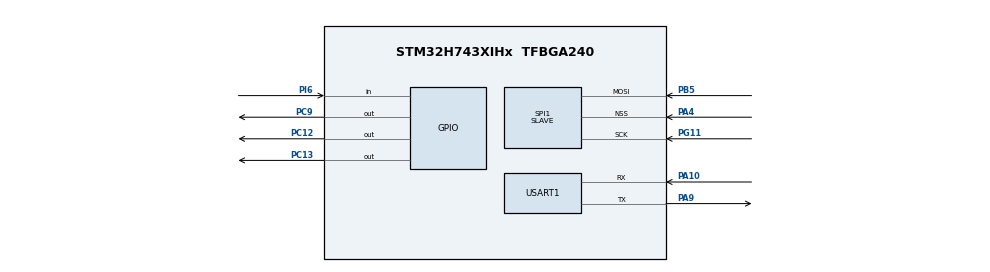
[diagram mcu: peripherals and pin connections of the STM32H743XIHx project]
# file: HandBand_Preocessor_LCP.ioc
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CORTEX_M7.CPU_DCache=Enabled
CORTEX_M7.CPU_ICache=Enabled
CORTEX_M7.default_mode_Activation=1
Dma.Request0=USART1_TX
Dma.Request1=SPI1_RX
Dma.SPI1_RX.1.Direction=DMA_PERIPH_TO_MEMORY
Dma.SPI1_RX.1.EventEnable=DISABLE
Dma.SPI1_RX.1.FIFOMode=DMA_FIFOMODE_DISABLE
Dma.SPI1_RX.1.Instance=DMA1_Stream1
Dma.SPI1_RX.1.MemDataAlignment=DMA_MDATAALIGN_BYTE
Dma.SPI1_RX.1.MemInc=DMA_MINC_ENABLE
Dma.SPI1_RX.1.Mode=DMA_NORMAL
Dma.SPI1_RX.1.PeriphDataAlignment=DMA_PDATAALIGN_BYTE
Dma.SPI1_RX.1.PeriphInc=DMA_PINC_DISABLE
Dma.SPI1_RX.1.Polarity=HAL_DMAMUX_REQ_GEN_RISING
Dma.SPI1_RX.1.Priority=DMA_PRIORITY_MEDIUM
Dma.SPI1_RX.1.RequestNumber=1
Dma.SPI1_RX.1.SignalID=NONE
Dma.SPI1_RX.1.SyncEnable=DISABLE
Dma.SPI1_RX.1.SyncPolarity=HAL_DMAMUX_SYNC_NO_EVENT
Dma.SPI1_RX.1.SyncRequestNumber=1
Dma.SPI1_RX.1.SyncSignalID=NONE
Dma.USART1_TX.0.Direction=DMA_MEMORY_TO_PERIPH
Dma.USART1_TX.0.EventEnable=DISABLE
Dma.USART1_TX.0.FIFOMode=DMA_FIFOMODE_DISABLE
Dma.USART1_TX.0.Instance=DMA1_Stream0
Dma.USART1_TX.0.MemDataAlignment=DMA_MDATAALIGN_BYTE
Dma.USART1_TX.0.MemInc=DMA_MINC_ENABLE
Dma.USART1_TX.0.Mode=DMA_NORMAL
Dma.USART1_TX.0.PeriphDataAlignment=DMA_PDATAALIGN_BYTE
Dma.USART1_TX.0.PeriphInc=DMA_PINC_DISABLE
Dma.USART1_TX.0.Polarity=HAL_DMAMUX_REQ_GEN_RISING
Dma.USART1_TX.0.Priority=DMA_PRIORITY_HIGH
Dma.USART1_TX.0.RequestNumber=1
Dma.USART1_TX.0.SignalID=NONE
Dma.USART1_TX.0.SyncEnable=DISABLE
Dma.USART1_TX.0.SyncPolarity=HAL_DMAMUX_SYNC_NO_EVENT
Dma.USART1_TX.0.SyncRequestNumber=1
Dma.USART1_TX.0.SyncSignalID=NONE
Mcu.Family=STM32H7
Mcu.Name=STM32H743XIHx
Mcu.Package=TFBGA240
NVIC.DMA1_Stream0_IRQn=true\:0\:0\:false\:false\:true\:false\:true\:true
NVIC.DMA1_Stream1_IRQn=true\:0\:0\:false\:false\:true\:false\:true\:true
NVIC.PriorityGroup=NVIC_PRIORITYGROUP_4
NVIC.SPI1_IRQn=true\:0\:0\:false\:false\:true\:true\:true\:true
NVIC.TIM17_IRQn=true\:15\:0\:false\:false\:true\:false\:true\:true
NVIC.TimeBase=TIM17_IRQn
NVIC.TimeBaseIP=TIM17
NVIC.USART1_IRQn=true\:0\:0\:false\:false\:true\:true\:true\:true
PA10.Mode=Asynchronous
PA10.Signal=USART1_RX
PA4.Mode=NSS_Signal_Hard_Input
PA4.Signal=SPI1_NSS
PA9.Mode=Asynchronous
PA9.Signal=USART1_TX
PB5.Mode=RX_Only_Simplex_Unidirect_Slave
PB5.Signal=SPI1_MOSI
PC12.Signal=GPIO_Output
PC13.Signal=GPIO_Output
PC9.Signal=GPIO_Output
PG11.Mode=RX_Only_Simplex_Unidirect_Slave
PG11.Signal=SPI1_SCK
PH0-OSC_IN\ (PH0).Mode=HSE-External-Oscillator
PH0-OSC_IN\ (PH0).Signal=RCC_OSC_IN
PH1-OSC_OUT\ (PH1).Mode=HSE-External-Oscillator
PH1-OSC_OUT\ (PH1).Signal=RCC_OSC_OUT
PI6.Signal=GPIO_Input
ProjectManager.HeapSize=0x200
ProjectManager.StackSize=0x400
ProjectManager.TargetToolchain=STM32CubeIDE
RCC.ADCFreq_Value=50390625
RCC.APB1Freq_Value=120000000
RCC.APB2Freq_Value=120000000
RCC.APB3Freq_Value=120000000
RCC.APB4Freq_Value=120000000
RCC.CortexFreq_Value=480000000
RCC.D1PPRE=RCC_APB3_DIV2
RCC.D2PPRE1=RCC_APB1_DIV2
RCC.D2PPRE2=RCC_APB2_DIV2
RCC.D3PPRE=RCC_APB4_DIV2
RCC.DIVM1=5
RCC.DIVM3=5
RCC.DIVN1=192
RCC.DIVN3=30
RCC.DIVP3=12
RCC.HCLKFreq_Value=240000000
RCC.HPRE=RCC_HCLK_DIV2
RCC.HSE_VALUE=25000000
RCC.PLL2FRACN=0
RCC.PLL3FRACN=0
RCC.PLLFRACN=0
RCC.PLLSourceVirtual=RCC_PLLSOURCE_HSE
RCC.SPI123CLockSelection=RCC_SPI123CLKSOURCE_PLL3
RCC.SYSCLKFreq_VALUE=480000000
RCC.SYSCLKSource=RCC_SYSCLKSOURCE_PLLCLK
RCC.USBFreq_Value=480000000
SPI1.DataSize=SPI_DATASIZE_8BIT
SPI1.Direction=SPI_DIRECTION_2LINES_RXONLY
SPI1.Mode=SPI_MODE_SLAVE
SPI1.VirtualNSS=VM_NSSHARD
SPI1.VirtualType=VM_SLAVE
USART1.VirtualMode-Asynchronous=VM_ASYNC
VP_MEMORYMAP_VS_MEMORYMAP.Mode=CurAppReg
VP_SYS_VS_tim17.Mode=TIM17
board=custom

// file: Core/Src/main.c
/* USER CODE BEGIN Header */
/**
 ******************************************************************************
 * @file           : main.c
 * @brief          : Main program body
 ******************************************************************************
 * @attention
 *
 * Copyright (c) 2025 STMicroelectronics.
 * All rights reserved.
 *
 * This software is licensed under terms that can be found in the LICENSE file
 * in the root directory of this software component.
 * If no LICENSE file comes with this software, it is provided AS-IS.
 *
 ******************************************************************************
 */
/* USER CODE END Header */
#include "main.h"
#include "dma.h"
#include "spi.h"
#include "usart.h"
#include "gpio.h"

/* USER CODE BEGIN Includes */
#include "string.h"
#include <stdio.h>

#include "vector.h"
#include "Listener.h"
#include "Controller.h"
#include "Presenter.h"
/* USER CODE END Includes */

/* USER CODE BEGIN PD */
#define Buffer_Size 50
/* USER CODE END PD */

void SystemClock_Config(void);
static void MPU_Config(void);

/* USER CODE BEGIN 0 */

//void HAL_SPI_RxCpltCallback(SPI_HandleTypeDef *hspi)
//{
//	if (hspi->Instance == SPI1) {
//		rx_flag = 1;
//		//HAL_SPI_Receive_DMA(&hspi1, &rx_data, 1);
//	}
//}

//void HAL_SPI_RxCpltCallback(SPI_HandleTypeDef *hspi)
//{
//    if (hspi->Instance == SPI1) {
//        SPI_flag = 1;  // 수신 완료 표시
//    }
//}

//UART를 DMA로 송신 완료 했다는 신호
//void HAL_UART_TxCpltCallback(UART_HandleTypeDef *huart)
//{
//    if (huart->Instance == USART1) {
//        // 전송 완료 처리
//        HAL_GPIO_TogglePin(GPIOC, GPIO_PIN_13);  // 예시: LED 토글
//    }
//}

/* USER CODE END 0 */

int main(void)
{

  /* USER CODE BEGIN 1 */
	//uint8_t SPI_flag = 0;
  /* USER CODE END 1 */

  /* MPU Configuration--------------------------------------------------------*/
  MPU_Config();

  /* Enable the CPU Cache */

  /* Enable I-Cache---------------------------------------------------------*/
  SCB_EnableICache();

  /* Enable D-Cache---------------------------------------------------------*/
  SCB_EnableDCache();

  /* MCU Configuration--------------------------------------------------------*/

  /* Reset of all peripherals, Initializes the Flash interface and the Systick. */
  HAL_Init();

  /* USER CODE BEGIN Init */
  Listener_Init();
  /* USER CODE END Init */

  /* Configure the system clock */
  SystemClock_Config();

  /* Initialize all configured peripherals */
  MX_GPIO_Init();
  MX_DMA_Init();
  MX_SPI1_Init();
  MX_USART1_UART_Init();
  /* USER CODE BEGIN 2 */
  controller_init();
  /* USER CODE END 2 */

  /* Infinite loop */
  /* USER CODE BEGIN WHILE */
	while (1)
	{
		if(!Listener_Execute()) continue;
		controller_excute();
		Presenter_Execute();
    /* USER CODE END WHILE */

	}
}

void SystemClock_Config(void)
{
  RCC_OscInitTypeDef RCC_OscInitStruct = {0};
  RCC_ClkInitTypeDef RCC_ClkInitStruct = {0};

  /** Supply configuration update enable
  */
  HAL_PWREx_ConfigSupply(PWR_LDO_SUPPLY);

  /** Configure the main internal regulator output voltage
  */
  __HAL_PWR_VOLTAGESCALING_CONFIG(PWR_REGULATOR_VOLTAGE_SCALE0);

  while(!__HAL_PWR_GET_FLAG(PWR_FLAG_VOSRDY)) {}

  /** Initializes the RCC Oscillators according to the specified parameters
  * in the RCC_OscInitTypeDef structure.
  */
  RCC_OscInitStruct.OscillatorType = RCC_OSCILLATORTYPE_HSE;
  RCC_OscInitStruct.HSEState = RCC_HSE_ON;
  RCC_OscInitStruct.PLL.PLLState = RCC_PLL_ON;
  RCC_OscInitStruct.PLL.PLLSource = RCC_PLLSOURCE_HSE;
  RCC_OscInitStruct.PLL.PLLM = 5;
  RCC_OscInitStruct.PLL.PLLN = 192;
  RCC_OscInitStruct.PLL.PLLP = 2;
  RCC_OscInitStruct.PLL.PLLQ = 2;
  RCC_OscInitStruct.PLL.PLLR = 2;
  RCC_OscInitStruct.PLL.PLLRGE = RCC_PLL1VCIRANGE_2;
  RCC_OscInitStruct.PLL.PLLVCOSEL = RCC_PLL1VCOWIDE;
  RCC_OscInitStruct.PLL.PLLFRACN = 0;
  if (HAL_RCC_OscConfig(&RCC_OscInitStruct) != HAL_OK)
  {
    Error_Handler();
  }

  /** Initializes the CPU, AHB and APB buses clocks
  */
  RCC_ClkInitStruct.ClockType = RCC_CLOCKTYPE_HCLK|RCC_CLOCKTYPE_SYSCLK
                              |RCC_CLOCKTYPE_PCLK1|RCC_CLOCKTYPE_PCLK2
                              |RCC_CLOCKTYPE_D3PCLK1|RCC_CLOCKTYPE_D1PCLK1;
  RCC_ClkInitStruct.SYSCLKSource = RCC_SYSCLKSOURCE_PLLCLK;
  RCC_ClkInitStruct.SYSCLKDivider = RCC_SYSCLK_DIV1;
  RCC_ClkInitStruct.AHBCLKDivider = RCC_HCLK_DIV2;
  RCC_ClkInitStruct.APB3CLKDivider = RCC_APB3_DIV2;
  RCC_ClkInitStruct.APB1CLKDivider = RCC_APB1_DIV2;
  RCC_ClkInitStruct.APB2CLKDivider = RCC_APB2_DIV2;
  RCC_ClkInitStruct.APB4CLKDivider = RCC_APB4_DIV2;

  if (HAL_RCC_ClockConfig(&RCC_ClkInitStruct, FLASH_LATENCY_4) != HAL_OK)
  {
    Error_Handler();
  }
}

 /* MPU Configuration */

void MPU_Config(void)
{
  MPU_Region_InitTypeDef MPU_InitStruct = {0};

  /* Disables the MPU */
  HAL_MPU_Disable();

  /** Initializes and configures the Region and the memory to be protected
  */
  MPU_InitStruct.Enable = MPU_REGION_ENABLE;
  MPU_InitStruct.Number = MPU_REGION_NUMBER0;
  MPU_InitStruct.BaseAddress = 0x0;
  MPU_InitStruct.Size = MPU_REGION_SIZE_4GB;
  MPU_InitStruct.SubRegionDisable = 0x87;
  MPU_InitStruct.TypeExtField = MPU_TEX_LEVEL0;
  MPU_InitStruct.AccessPermission = MPU_REGION_NO_ACCESS;
  MPU_InitStruct.DisableExec = MPU_INSTRUCTION_ACCESS_DISABLE;
  MPU_InitStruct.IsShareable = MPU_ACCESS_SHAREABLE;
  MPU_InitStruct.IsCacheable = MPU_ACCESS_NOT_CACHEABLE;
  MPU_InitStruct.IsBufferable = MPU_ACCESS_NOT_BUFFERABLE;

  HAL_MPU_ConfigRegion(&MPU_InitStruct);
  /* Enables the MPU */
  HAL_MPU_Enable(MPU_PRIVILEGED_DEFAULT);

}

void HAL_TIM_PeriodElapsedCallback(TIM_HandleTypeDef *htim)
{
  if (htim->Instance == TIM17)
  {
    HAL_IncTick();
  }
}

void Error_Handler(void)
{
	__disable_irq();
	while (1)
	{
	}
}
